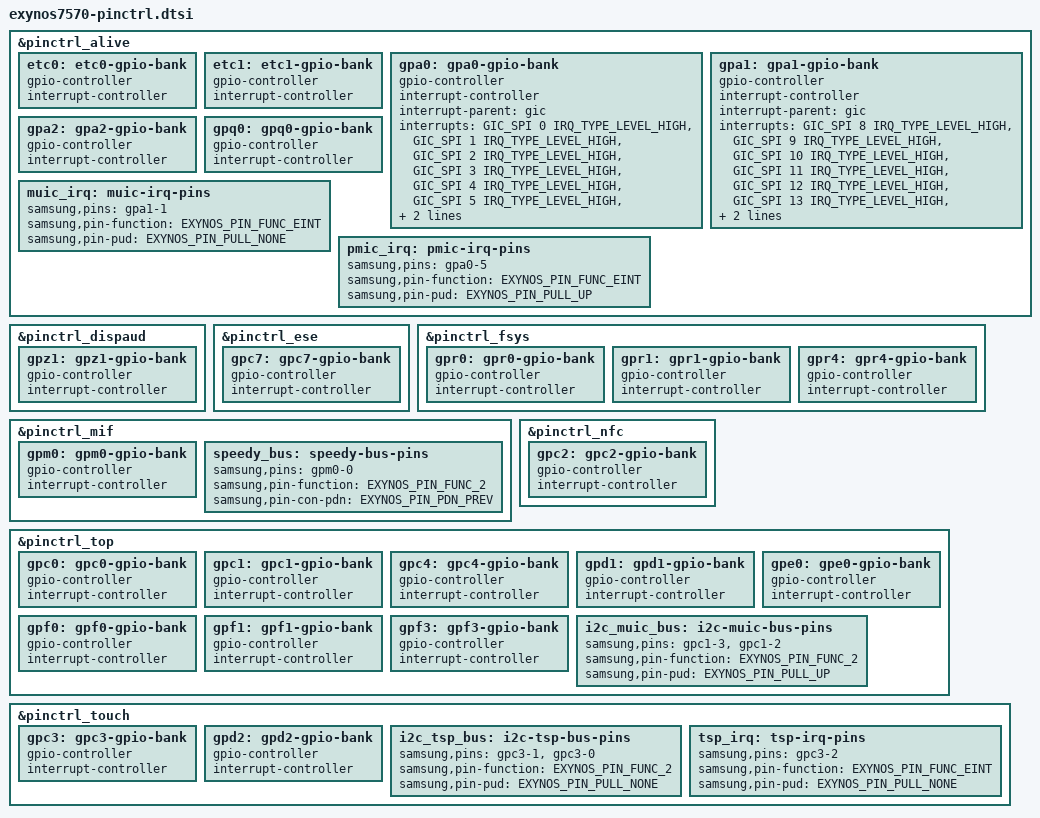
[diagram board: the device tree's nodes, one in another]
// SPDX-License-Identifier: GPL-2.0
/*
 * Samsung Exynos7570 SoC pin-mux and pin-config device tree source
 *
 * Copyright (c) 2016 Samsung Electronics Co., Ltd.
 */

#include <dt-bindings/interrupt-controller/arm-gic.h>
#include "exynos-pinctrl.h"

&pinctrl_alive {
	etc0: etc0-gpio-bank {
		gpio-controller;
		#gpio-cells = <2>;

		interrupt-controller;
		#interrupt-cells = <2>;
	};

	etc1: etc1-gpio-bank {
		gpio-controller;
		#gpio-cells = <2>;

		interrupt-controller;
		#interrupt-cells = <2>;
	};

	gpa0: gpa0-gpio-bank {
		gpio-controller;
		#gpio-cells = <2>;

		interrupt-controller;
		#interrupt-cells = <2>;
		interrupt-parent = <&gic>;
		interrupts = <GIC_SPI 0 IRQ_TYPE_LEVEL_HIGH>,
			     <GIC_SPI 1 IRQ_TYPE_LEVEL_HIGH>,
			     <GIC_SPI 2 IRQ_TYPE_LEVEL_HIGH>,
			     <GIC_SPI 3 IRQ_TYPE_LEVEL_HIGH>,
			     <GIC_SPI 4 IRQ_TYPE_LEVEL_HIGH>,
			     <GIC_SPI 5 IRQ_TYPE_LEVEL_HIGH>,
			     <GIC_SPI 6 IRQ_TYPE_LEVEL_HIGH>,
			     <GIC_SPI 7 IRQ_TYPE_LEVEL_HIGH>;
	};

	gpa1: gpa1-gpio-bank {
		gpio-controller;
		#gpio-cells = <2>;

		interrupt-controller;
		#interrupt-cells = <2>;
		interrupt-parent = <&gic>;
		interrupts = <GIC_SPI 8 IRQ_TYPE_LEVEL_HIGH>,
			     <GIC_SPI 9 IRQ_TYPE_LEVEL_HIGH>,
			     <GIC_SPI 10 IRQ_TYPE_LEVEL_HIGH>,
			     <GIC_SPI 11 IRQ_TYPE_LEVEL_HIGH>,
			     <GIC_SPI 12 IRQ_TYPE_LEVEL_HIGH>,
			     <GIC_SPI 13 IRQ_TYPE_LEVEL_HIGH>,
			     <GIC_SPI 14 IRQ_TYPE_LEVEL_HIGH>,
			     <GIC_SPI 15 IRQ_TYPE_LEVEL_HIGH>;
	};

	gpa2: gpa2-gpio-bank {
		gpio-controller;
		#gpio-cells = <2>;

		interrupt-controller;
		#interrupt-cells = <2>;
	};

	gpq0: gpq0-gpio-bank {
		gpio-controller;
		#gpio-cells = <2>;

		interrupt-controller;
		#interrupt-cells = <2>;
	};
};

&pinctrl_dispaud {
	gpz1: gpz1-gpio-bank {
		gpio-controller;
		#gpio-cells = <2>;

		interrupt-controller;
		#interrupt-cells = <2>;
	};
};

&pinctrl_ese {
	gpc7: gpc7-gpio-bank {
		gpio-controller;
		#gpio-cells = <2>;

		interrupt-controller;
		#interrupt-cells = <2>;
	};
};

&pinctrl_fsys {
	gpr0: gpr0-gpio-bank {
		gpio-controller;
		#gpio-cells = <2>;

		interrupt-controller;
		#interrupt-cells = <2>;
	};

	gpr1: gpr1-gpio-bank {
		gpio-controller;
		#gpio-cells = <2>;

		interrupt-controller;
		#interrupt-cells = <2>;
	};

	gpr4: gpr4-gpio-bank {
		gpio-controller;
		#gpio-cells = <2>;

		interrupt-controller;
		#interrupt-cells = <2>;
	};
};

&pinctrl_alive {
	muic_irq: muic-irq-pins {
		samsung,pins = "gpa1-1";
		samsung,pin-function = <EXYNOS_PIN_FUNC_EINT>;
		samsung,pin-pud = <EXYNOS_PIN_PULL_NONE>;
	};

	pmic_irq: pmic-irq-pins {
		samsung,pins = "gpa0-5";
		samsung,pin-function = <EXYNOS_PIN_FUNC_EINT>;
		samsung,pin-pud = <EXYNOS_PIN_PULL_UP>;
	};
};

&pinctrl_mif {
	gpm0: gpm0-gpio-bank {
		gpio-controller;
		#gpio-cells = <2>;

		interrupt-controller;
		#interrupt-cells = <2>;
	};
};

&pinctrl_nfc {
	gpc2: gpc2-gpio-bank {
		gpio-controller;
		#gpio-cells = <2>;

		interrupt-controller;
		#interrupt-cells = <2>;
	};
};

&pinctrl_top {
	gpc0: gpc0-gpio-bank {
		gpio-controller;
		#gpio-cells = <2>;

		interrupt-controller;
		#interrupt-cells = <2>;
	};

	gpc1: gpc1-gpio-bank {
		gpio-controller;
		#gpio-cells = <2>;

		interrupt-controller;
		#interrupt-cells = <2>;
	};

	gpc4: gpc4-gpio-bank {
		gpio-controller;
		#gpio-cells = <2>;

		interrupt-controller;
		#interrupt-cells = <2>;
	};

	gpd1: gpd1-gpio-bank {
		gpio-controller;
		#gpio-cells = <2>;

		interrupt-controller;
		#interrupt-cells = <2>;
	};

	gpe0: gpe0-gpio-bank {
		gpio-controller;
		#gpio-cells = <2>;

		interrupt-controller;
		#interrupt-cells = <2>;
	};

	gpf0: gpf0-gpio-bank {
		gpio-controller;
		#gpio-cells = <2>;

		interrupt-controller;
		#interrupt-cells = <2>;
	};

	gpf1: gpf1-gpio-bank {
		gpio-controller;
		#gpio-cells = <2>;

		interrupt-controller;
		#interrupt-cells = <2>;
	};

	gpf3: gpf3-gpio-bank {
		gpio-controller;
		#gpio-cells = <2>;

		interrupt-controller;
		#interrupt-cells = <2>;
	};
};

&pinctrl_touch {
	gpc3: gpc3-gpio-bank {
		gpio-controller;
		#gpio-cells = <2>;

		interrupt-controller;
		#interrupt-cells = <2>;
	};

	gpd2: gpd2-gpio-bank {
		gpio-controller;
		#gpio-cells = <2>;

		interrupt-controller;
		#interrupt-cells = <2>;
	};
};

&pinctrl_mif {
	speedy_bus: speedy-bus-pins {
		samsung,pins = "gpm0-0";
		samsung,pin-function = <EXYNOS_PIN_FUNC_2>;
		samsung,pin-con-pdn = <EXYNOS_PIN_PDN_PREV>;
	};
};

&pinctrl_top {
	i2c_muic_bus: i2c-muic-bus-pins {
		samsung,pins = "gpc1-3", "gpc1-2";
		samsung,pin-function = <EXYNOS_PIN_FUNC_2>;
		samsung,pin-pud = <EXYNOS_PIN_PULL_UP>;
	};
};

&pinctrl_touch {
	i2c_tsp_bus: i2c-tsp-bus-pins {
		samsung,pins = "gpc3-1", "gpc3-0";
		samsung,pin-function = <EXYNOS_PIN_FUNC_2>;
		samsung,pin-pud = <EXYNOS_PIN_PULL_NONE>;
	};

	tsp_irq: tsp-irq-pins {
		samsung,pins = "gpc3-2";
		samsung,pin-function = <EXYNOS_PIN_FUNC_EINT>;
		samsung,pin-pud = <EXYNOS_PIN_PULL_NONE>;
	};
};
